# MCXN947_cm33_core0 register map
Vendor: nxp.com; File version: 1.0
CPU: CM33 r2p0, little endian, MPU, FPU, VTOR, 3 interrupt priority bits
Registers are 32-bit, read-write, reset 0x0 unless marked. A register's access mark holds for its fields unless they carry their own. Offsets are from the block's base; [hi:lo] are bit positions; {n}, {i} and the like mark numbered series; 'fields as' and 'values as' point back to an identical list.

## TRDC
Base 0x400C6000
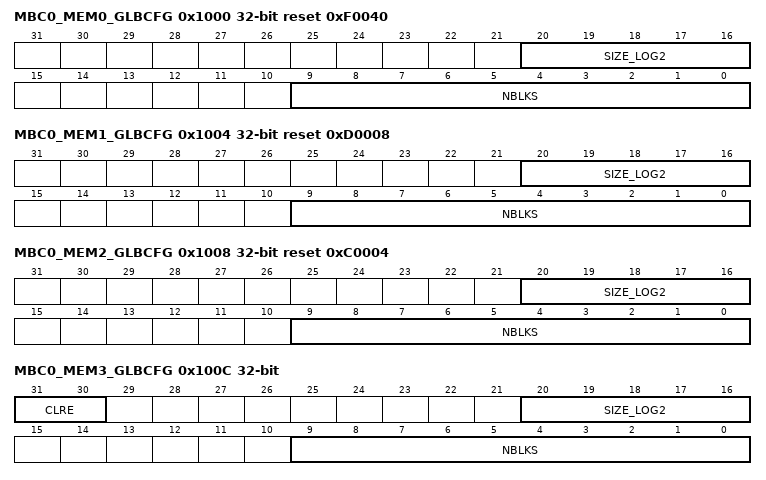
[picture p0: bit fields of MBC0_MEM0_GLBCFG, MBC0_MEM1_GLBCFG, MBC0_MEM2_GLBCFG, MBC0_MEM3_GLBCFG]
0x1000 MBC0_MEM0_GLBCFG ro reset 0xF0040 — MBC Global Configuration Register
  [20:16] SIZE_LOG2 — Log2 size per block
  [9:0] NBLKS — Number of blocks in this memory
0x1004 MBC0_MEM1_GLBCFG ro reset 0xD0008 — MBC Global Configuration Register
  fields as MBC0_MEM0_GLBCFG
0x1008 MBC0_MEM2_GLBCFG ro reset 0xC0004 — MBC Global Configuration Register
  fields as MBC0_MEM0_GLBCFG
0x100C MBC0_MEM3_GLBCFG — MBC Global Configuration Register
  [31:30] CLRE — Clear Error
  [20:16] SIZE_LOG2 ro — Log2 size per block
  [9:0] NBLKS ro — Number of blocks in this memory
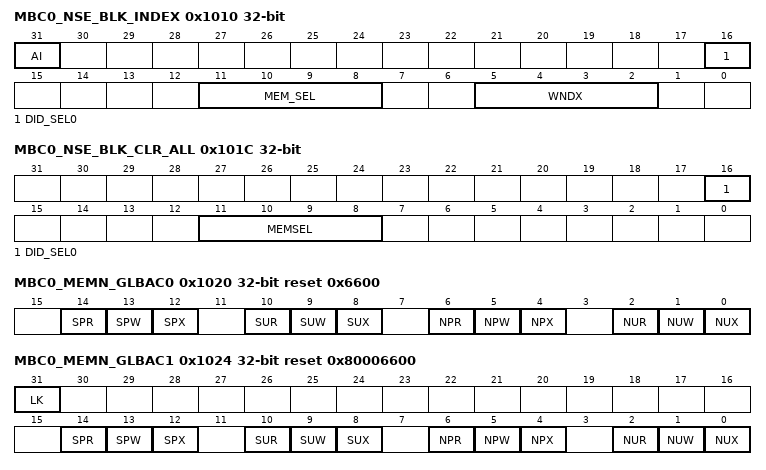
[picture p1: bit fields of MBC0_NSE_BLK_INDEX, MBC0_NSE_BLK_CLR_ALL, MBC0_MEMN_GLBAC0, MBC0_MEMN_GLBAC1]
0x1010 MBC0_NSE_BLK_INDEX — MBC NonSecure Enable Block Index
  [31] AI — Auto Increment
    0=LOGIC_0 (No effect.); 1=LOGIC_1 (Add 1 to the WNDX field after the register write.)
  [16] DID_SEL0 — DID Select
    0=LOGIC_0 (No effect.); 1=LOGIC_1 (Selects NSE bits for this domain.)
  [11:8] MEM_SEL — Memory Select
  [5:2] WNDX — Word index into the block NSE bitmap. It selects the BLK_NSE_Wn register, where WNDX determines the value of n.
0x1014 MBC0_NSE_BLK_SET — MBC NonSecure Enable Block Set
  [31:0] W1SET — Write-1 Set
0x1018 MBC0_NSE_BLK_CLR — MBC NonSecure Enable Block Clear
  [31:0] W1CLR — Write-1 Clear
0x101C MBC0_NSE_BLK_CLR_ALL — MBC NonSecure Enable Block Clear All
  [16] DID_SEL0 — DID Select
    0=LOGIC_0 (No effect.); 1=LOGIC_1 (Clear all NSE bits for this domain.)
  [11:8] MEMSEL — Memory Select
0x1020 MBC0_MEMN_GLBAC0 reset 0x6600 — MBC Global Access Control
  [14] SPR — SecurePriv Read
    0=NOTALLOWED (Read access is not allowed in Secure Privilege mode.); 1=ALLOWED (Read access is allowed in Secure Privilege mode.)
  [13] SPW — SecurePriv Write
    0=NOTALLOWED (Write access is not allowed in Secure Privilege mode.); 1=ALLOWED (Write access is allowed in Secure Privilege mode.)
  [12] SPX — SecurePriv Execute
    0=NOTALLOWED (Execute access is not allowed in Secure Privilege mode.); 1=ALLOWED (Execute access is allowed in Secure Privilege mode.)
  [10] SUR — SecureUser Read
    0=NOTALLOWED (Read access is not allowed in Secure User mode.); 1=ALLOWED (Read access is allowed in Secure User mode.)
  [9] SUW — SecureUser Write
    0=NOTALLOWED (Write access is not allowed in Secure User mode.); 1=ALLOWED (Write access is allowed in Secure User mode.)
  [8] SUX — SecureUser Execute
    0=NOTALLOWED (Execute access is not allowed in Secure User mode.); 1=ALLOWED (Execute access is allowed in Secure User mode.)
  [6] NPR — NonsecurePriv Read
    0=NOTALLOWED (Read access is not allowed in Nonsecure Privilege mode.); 1=ALLOWED (Read access is allowed in Nonsecure Privilege mode.)
  [5] NPW — NonsecurePriv Write
    0=NOTALLOWED (Write access is not allowed in Nonsecure Privilege mode.); 1=ALLOWED (Write access is allowed in Nonsecure Privilege mode.)
  [4] NPX — NonsecurePriv Execute
    0=NOTALLOWED (Execute access is not allowed in Nonsecure Privilege mode.); 1=ALLOWED (Execute access is allowed in Nonsecure Privilege mode.)
  [2] NUR — NonsecureUser Read
    0=NOTALLOWED (Read access is not allowed in Nonsecure User mode.); 1=ALLOWED (Read access is allowed in Nonsecure User mode.)
  [1] NUW — NonsecureUser Write
    0=NOTALLOWED (Write access is not allowed in Nonsecure User mode.); 1=ALLOWED (Write access is allowed in Nonsecure User mode.)
  [0] NUX — NonsecureUser Execute
    0=NOTALLOWED (Execute access is not allowed in Nonsecure User mode.); 1=ALLOWED (Execute access is allowed in Nonsecure User mode.)
0x1024 MBC0_MEMN_GLBAC1 reset 0x80006600 — MBC Global Access Control
  [31] LK — LOCK
    0=UNLOCKED (This register is not locked and can be altered.); 1=LOCKED (This register is locked and cannot be altered.)
  [14] SPR — SecurePriv Read
    values as MBC0_MEMN_GLBAC0.SPR
  [13] SPW — SecurePriv Write
    values as MBC0_MEMN_GLBAC0.SPW
  [12] SPX — SecurePriv Execute
    values as MBC0_MEMN_GLBAC0.SPX
  [10] SUR — SecureUser Read
    values as MBC0_MEMN_GLBAC0.SUR
  [9] SUW — SecureUser Write
    values as MBC0_MEMN_GLBAC0.SUW
  [8] SUX — SecureUser Execute
    values as MBC0_MEMN_GLBAC0.SUX
  [6] NPR — NonsecurePriv Read
    values as MBC0_MEMN_GLBAC0.NPR
  [5] NPW — NonsecurePriv Write
    values as MBC0_MEMN_GLBAC0.NPW
  [4] NPX — NonsecurePriv Execute
    values as MBC0_MEMN_GLBAC0.NPX
  [2] NUR — NonsecureUser Read
    values as MBC0_MEMN_GLBAC0.NUR
  [1] NUW — NonsecureUser Write
    values as MBC0_MEMN_GLBAC0.NUW
  [0] NUX — NonsecureUser Execute
    values as MBC0_MEMN_GLBAC0.NUX
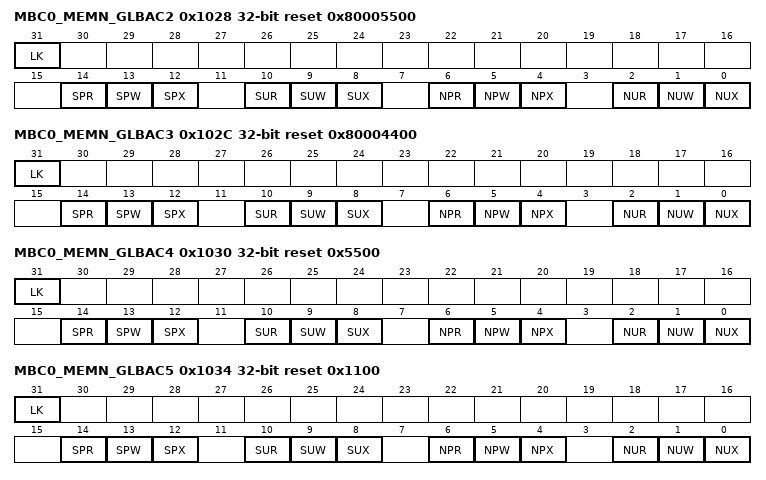
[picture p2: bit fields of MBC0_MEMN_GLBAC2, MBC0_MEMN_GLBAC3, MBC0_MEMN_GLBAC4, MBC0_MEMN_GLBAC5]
0x1028 MBC0_MEMN_GLBAC2 reset 0x80005500 — MBC Global Access Control
  fields as MBC0_MEMN_GLBAC1
0x102C MBC0_MEMN_GLBAC3 reset 0x80004400 — MBC Global Access Control
  fields as MBC0_MEMN_GLBAC1
0x1030 MBC0_MEMN_GLBAC4 reset 0x5500 — MBC Global Access Control
  fields as MBC0_MEMN_GLBAC1
0x1034 MBC0_MEMN_GLBAC5 reset 0x1100 — MBC Global Access Control
  fields as MBC0_MEMN_GLBAC1
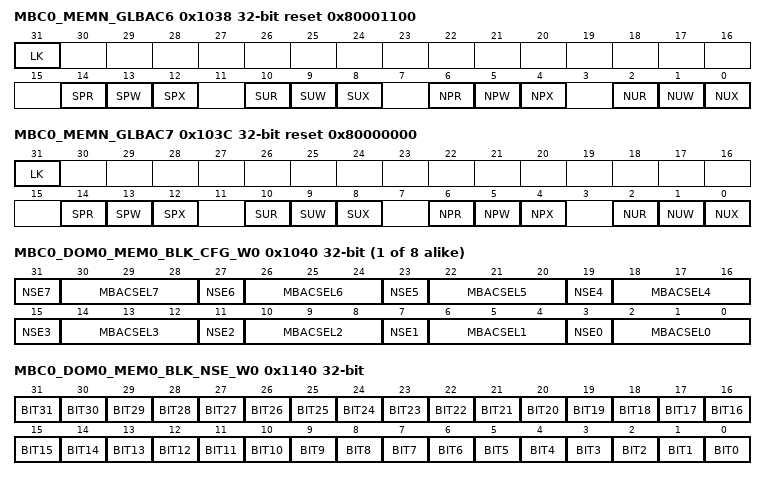
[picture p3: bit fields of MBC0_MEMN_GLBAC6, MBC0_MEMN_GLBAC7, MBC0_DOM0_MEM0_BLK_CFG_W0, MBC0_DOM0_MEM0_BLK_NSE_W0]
0x1038 MBC0_MEMN_GLBAC6 reset 0x80001100 — MBC Global Access Control
  fields as MBC0_MEMN_GLBAC1
0x103C MBC0_MEMN_GLBAC7 reset 0x80000000 — MBC Global Access Control
  fields as MBC0_MEMN_GLBAC1
{0x1040+4i} MBC0_DOM0_MEM0_BLK_CFG_W{i} (i=0..7) — MBC Memory Block Configuration Word
  [4n+3] NSE{n} (n=0..7) — NonSecure Enable for block B
    0=ALLOWED (Secure accesses to block B are based on corresponding MBACSEL field in this register (MBCm_DOMd_MEMs_BLK_CFG_Ww[MBACSEL]), nonsecure accesses to block B are not allowed.); 1=NOTALLOWED (Secure accesses to block B are not allowed, nonsecure accesses to block B are based on corresponding MBACSEL field in this register (MBCm_DOMd_MEMs_BLK_CFG_Ww[MBACSEL]).)
  [4n+2:4n] MBACSEL{n} (n=0..7) — Memory Block Access Control Select for block B
    {v}=GLBAC{v} (select MBC_MEMN_GLBAC{v} access control policy for block B) (v=0..7)
0x1140 MBC0_DOM0_MEM0_BLK_NSE_W0 — MBC Memory Block NonSecure Enable Word
  [all] fields
    0=ALLOWED (Secure accesses to block B are based on corresponding MBACSEL field in register (MBCm_DOMd_MEMs_BLK_CFG_Ww[MBACSEL]), nonsecure accesses to block B are not allowed.); 1=NOTALLOWED (Secure accesses to block B are not allowed, nonsecure accesses to block B are based on corresponding MBACSEL field in register (MBCm_DOMd_MEMs_BLK_CFG_Ww[MBACSEL]).)
  [n] BIT{n} (n=0..31) — Bit b NonSecure Enable [b = 0 - 31]
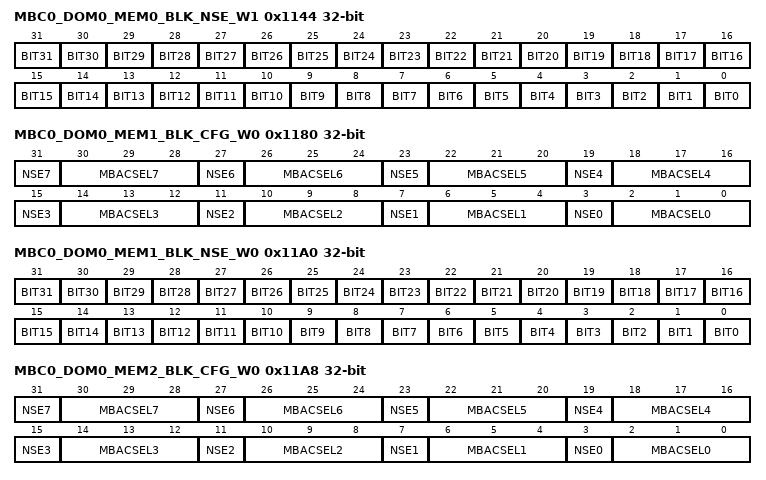
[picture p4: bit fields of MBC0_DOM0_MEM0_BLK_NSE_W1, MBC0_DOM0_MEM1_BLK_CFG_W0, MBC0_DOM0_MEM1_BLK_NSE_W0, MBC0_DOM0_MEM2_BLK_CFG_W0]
0x1144 MBC0_DOM0_MEM0_BLK_NSE_W1 — MBC Memory Block NonSecure Enable Word
  fields as MBC0_DOM0_MEM0_BLK_NSE_W0
0x1180 MBC0_DOM0_MEM1_BLK_CFG_W0 — MBC Memory Block Configuration Word
  fields as MBC0_DOM0_MEM0_BLK_CFG_W0
0x11A0 MBC0_DOM0_MEM1_BLK_NSE_W0 — MBC Memory Block NonSecure Enable Word
  fields as MBC0_DOM0_MEM0_BLK_NSE_W0
0x11A8 MBC0_DOM0_MEM2_BLK_CFG_W0 — MBC Memory Block Configuration Word
  fields as MBC0_DOM0_MEM0_BLK_CFG_W0
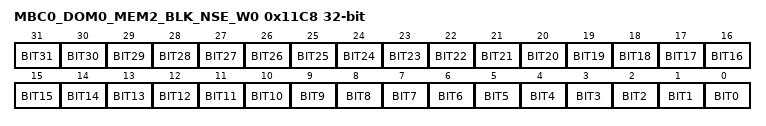
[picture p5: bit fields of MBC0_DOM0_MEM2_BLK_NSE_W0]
0x11C8 MBC0_DOM0_MEM2_BLK_NSE_W0 — MBC Memory Block NonSecure Enable Word
  fields as MBC0_DOM0_MEM0_BLK_NSE_W0
